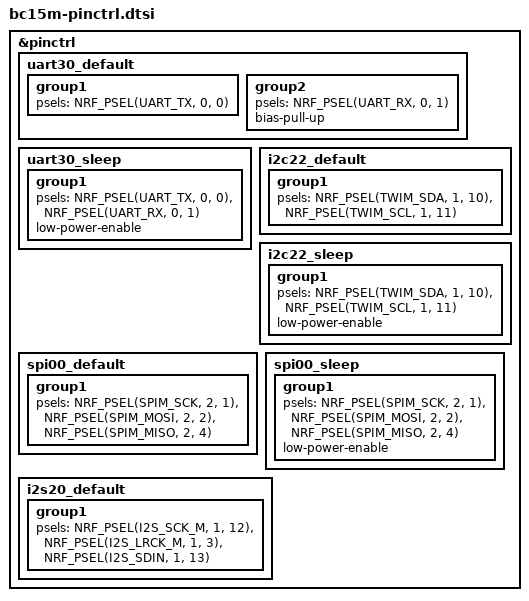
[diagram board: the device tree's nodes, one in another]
&pinctrl {
	/omit-if-no-ref/ uart30_default: uart30_default {
		group1 {
			psels = <NRF_PSEL(UART_TX, 0, 0)>;
		};

		group2 {
			psels = <NRF_PSEL(UART_RX, 0, 1)>;
			bias-pull-up;
		};
	};

	/omit-if-no-ref/ uart30_sleep: uart30_sleep {
		group1 {
			psels = <NRF_PSEL(UART_TX, 0, 0)>,
				<NRF_PSEL(UART_RX, 0, 1)>;
			low-power-enable;
		};
	};

	/omit-if-no-ref/ i2c22_default: i2c22_default {
		group1 {
			psels = <NRF_PSEL(TWIM_SDA, 1, 10)>,
				<NRF_PSEL(TWIM_SCL, 1, 11)>;
		};
	};

	/omit-if-no-ref/ i2c22_sleep: i2c22_sleep {
		group1 {
			psels = <NRF_PSEL(TWIM_SDA, 1, 10)>,
				<NRF_PSEL(TWIM_SCL, 1, 11)>;
			low-power-enable;
		};
	};

	/omit-if-no-ref/ spi00_default: spi00_default {
		group1 {
			psels = <NRF_PSEL(SPIM_SCK, 2, 1)>,
				<NRF_PSEL(SPIM_MOSI, 2, 2)>,
				<NRF_PSEL(SPIM_MISO, 2, 4)>;
		};
	};

	/omit-if-no-ref/ spi00_sleep: spi00_sleep {
		group1 {
			psels = <NRF_PSEL(SPIM_SCK, 2, 1)>,
				<NRF_PSEL(SPIM_MOSI, 2, 2)>,
				<NRF_PSEL(SPIM_MISO, 2, 4)>;
			low-power-enable;
		};
	};

	/omit-if-no-ref/ i2s20_default: i2s20_default {
		group1 {
			psels = <NRF_PSEL(I2S_SCK_M, 1, 12)>,
				<NRF_PSEL(I2S_LRCK_M, 1, 3)>,
				<NRF_PSEL(I2S_SDIN, 1, 13)>;
		};
	};
};
